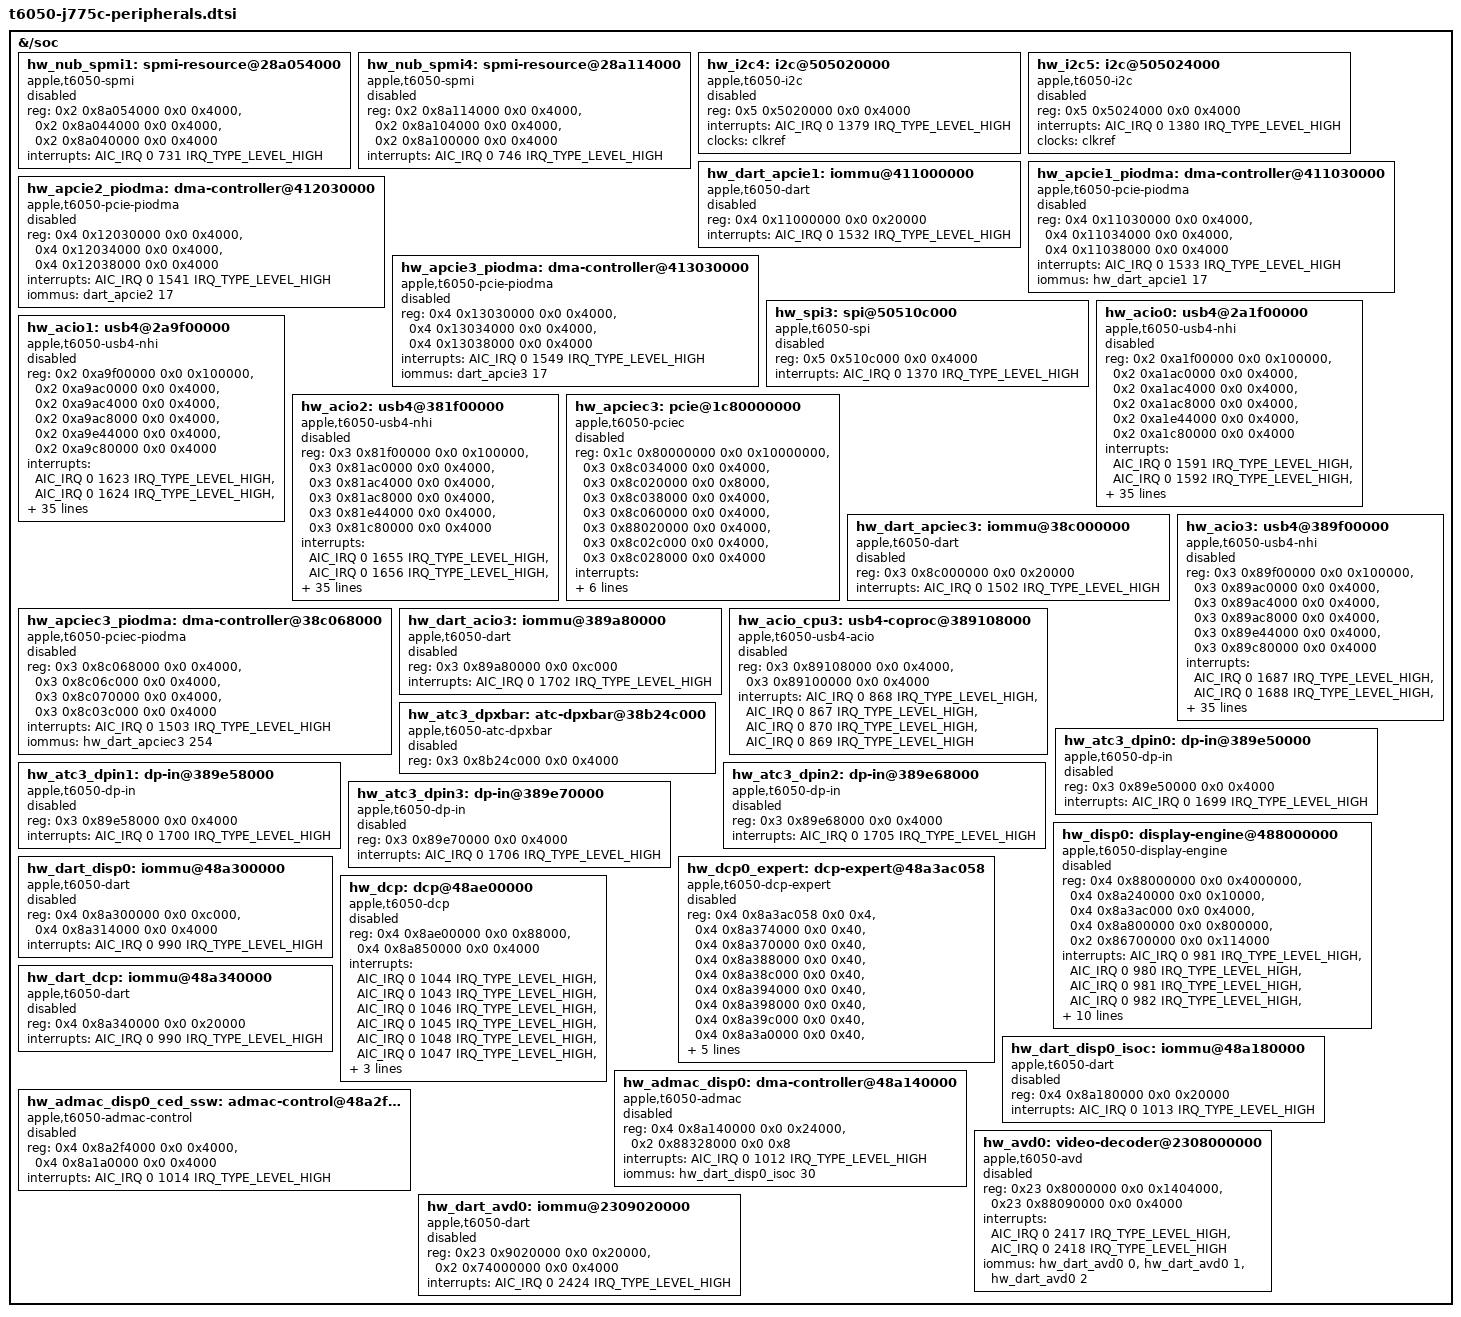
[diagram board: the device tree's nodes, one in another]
#include "t6050-peripherals.dtsi"

// SPDX-License-Identifier: GPL-2.0+ OR MIT
/* Register and interrupt resources; ownership-sensitive blocks stay disabled. */

&{/soc} {
	hw_nub_spmi1: spmi-resource@28a054000 {
		compatible = "apple,t6050-spmi", "apple,spmi";
		reg = <0x2 0x8a054000 0x0 0x4000>,
		      <0x2 0x8a044000 0x0 0x4000>,
		      <0x2 0x8a040000 0x0 0x4000>;
		status = "disabled";
		interrupts = <AIC_IRQ 0 731 IRQ_TYPE_LEVEL_HIGH>;
	};

	hw_nub_spmi4: spmi-resource@28a114000 {
		compatible = "apple,t6050-spmi", "apple,spmi";
		reg = <0x2 0x8a114000 0x0 0x4000>,
		      <0x2 0x8a104000 0x0 0x4000>,
		      <0x2 0x8a100000 0x0 0x4000>;
		status = "disabled";
		interrupts = <AIC_IRQ 0 746 IRQ_TYPE_LEVEL_HIGH>;
	};

	hw_i2c4: i2c@505020000 {
		compatible = "apple,t6050-i2c", "apple,t8103-i2c";
		reg = <0x5 0x5020000 0x0 0x4000>;
		interrupts = <AIC_IRQ 0 1379 IRQ_TYPE_LEVEL_HIGH>;
		status = "disabled";
		clocks = <&clkref>;
		#address-cells = <1>;
		#size-cells = <0>;
	};

	hw_i2c5: i2c@505024000 {
		compatible = "apple,t6050-i2c", "apple,t8103-i2c";
		reg = <0x5 0x5024000 0x0 0x4000>;
		interrupts = <AIC_IRQ 0 1380 IRQ_TYPE_LEVEL_HIGH>;
		status = "disabled";
		clocks = <&clkref>;
		#address-cells = <1>;
		#size-cells = <0>;
	};

	hw_dart_apcie1: iommu@411000000 {
		compatible = "apple,t6050-dart", "apple,dart";
		reg = <0x4 0x11000000 0x0 0x20000>;
		#iommu-cells = <1>;
		interrupts = <AIC_IRQ 0 1532 IRQ_TYPE_LEVEL_HIGH>;
		status = "disabled";
	};

	hw_apcie1_piodma: dma-controller@411030000 {
		compatible = "apple,t6050-pcie-piodma", "apple,pcie-piodma";
		reg = <0x4 0x11030000 0x0 0x4000>,
		      <0x4 0x11034000 0x0 0x4000>,
		      <0x4 0x11038000 0x0 0x4000>;
		interrupts = <AIC_IRQ 0 1533 IRQ_TYPE_LEVEL_HIGH>;
		iommus = <&hw_dart_apcie1 17>;
		status = "disabled";
	};

	hw_apcie2_piodma: dma-controller@412030000 {
		compatible = "apple,t6050-pcie-piodma", "apple,pcie-piodma";
		reg = <0x4 0x12030000 0x0 0x4000>,
		      <0x4 0x12034000 0x0 0x4000>,
		      <0x4 0x12038000 0x0 0x4000>;
		interrupts = <AIC_IRQ 0 1541 IRQ_TYPE_LEVEL_HIGH>;
		iommus = <&dart_apcie2 17>;
		status = "disabled";
	};

	hw_apcie3_piodma: dma-controller@413030000 {
		compatible = "apple,t6050-pcie-piodma", "apple,pcie-piodma";
		reg = <0x4 0x13030000 0x0 0x4000>,
		      <0x4 0x13034000 0x0 0x4000>,
		      <0x4 0x13038000 0x0 0x4000>;
		interrupts = <AIC_IRQ 0 1549 IRQ_TYPE_LEVEL_HIGH>;
		iommus = <&dart_apcie3 17>;
		status = "disabled";
	};

	hw_spi3: spi@50510c000 {
		compatible = "apple,t6050-spi", "apple,spi";
		reg = <0x5 0x510c000 0x0 0x4000>;
		interrupts = <AIC_IRQ 0 1370 IRQ_TYPE_LEVEL_HIGH>;
		status = "disabled";
	};

	hw_acio0: usb4@2a1f00000 {
		compatible = "apple,t6050-usb4-nhi", "apple,usb4-nhi";
		reg = <0x2 0xa1f00000 0x0 0x100000>,
		      <0x2 0xa1ac0000 0x0 0x4000>,
		      <0x2 0xa1ac4000 0x0 0x4000>,
		      <0x2 0xa1ac8000 0x0 0x4000>,
		      <0x2 0xa1e44000 0x0 0x4000>,
		      <0x2 0xa1c80000 0x0 0x4000>;
		interrupts = <AIC_IRQ 0 1591 IRQ_TYPE_LEVEL_HIGH>,
			     <AIC_IRQ 0 1592 IRQ_TYPE_LEVEL_HIGH>,
			     <AIC_IRQ 0 1593 IRQ_TYPE_LEVEL_HIGH>,
			     <AIC_IRQ 0 1594 IRQ_TYPE_LEVEL_HIGH>,
			     <AIC_IRQ 0 1595 IRQ_TYPE_LEVEL_HIGH>,
			     <AIC_IRQ 0 1596 IRQ_TYPE_LEVEL_HIGH>,
			     <AIC_IRQ 0 1597 IRQ_TYPE_LEVEL_HIGH>,
			     <AIC_IRQ 0 1598 IRQ_TYPE_LEVEL_HIGH>,
			     <AIC_IRQ 0 1599 IRQ_TYPE_LEVEL_HIGH>,
			     <AIC_IRQ 0 1600 IRQ_TYPE_LEVEL_HIGH>,
			     <AIC_IRQ 0 1601 IRQ_TYPE_LEVEL_HIGH>,
			     <AIC_IRQ 0 1602 IRQ_TYPE_LEVEL_HIGH>,
			     <AIC_IRQ 0 1579 IRQ_TYPE_LEVEL_HIGH>,
			     <AIC_IRQ 0 1580 IRQ_TYPE_LEVEL_HIGH>,
			     <AIC_IRQ 0 1581 IRQ_TYPE_LEVEL_HIGH>,
			     <AIC_IRQ 0 1582 IRQ_TYPE_LEVEL_HIGH>,
			     <AIC_IRQ 0 1583 IRQ_TYPE_LEVEL_HIGH>,
			     <AIC_IRQ 0 1584 IRQ_TYPE_LEVEL_HIGH>,
			     <AIC_IRQ 0 1585 IRQ_TYPE_LEVEL_HIGH>,
			     <AIC_IRQ 0 1586 IRQ_TYPE_LEVEL_HIGH>,
			     <AIC_IRQ 0 1587 IRQ_TYPE_LEVEL_HIGH>,
			     <AIC_IRQ 0 1588 IRQ_TYPE_LEVEL_HIGH>,
			     <AIC_IRQ 0 1589 IRQ_TYPE_LEVEL_HIGH>,
			     <AIC_IRQ 0 1590 IRQ_TYPE_LEVEL_HIGH>,
			     <AIC_IRQ 0 1608 IRQ_TYPE_LEVEL_HIGH>;
		iommus = <&hw_dart_acio0 0>, <&hw_dart_acio0 1>, <&hw_dart_acio0 2>, <&hw_dart_acio0 3>, <&hw_dart_acio0 4>, <&hw_dart_acio0 5>, <&hw_dart_acio0 6>, <&hw_dart_acio0 7>, <&hw_dart_acio0 8>, <&hw_dart_acio0 9>, <&hw_dart_acio0 10>, <&hw_dart_acio0 11>, <&hw_dart_acio0 16>, <&hw_dart_acio0 17>, <&hw_dart_acio0 18>, <&hw_dart_acio0 19>, <&hw_dart_acio0 20>, <&hw_dart_acio0 21>, <&hw_dart_acio0 22>, <&hw_dart_acio0 23>, <&hw_dart_acio0 24>, <&hw_dart_acio0 25>, <&hw_dart_acio0 26>, <&hw_dart_acio0 27>;
		status = "disabled";
	};

	hw_acio1: usb4@2a9f00000 {
		compatible = "apple,t6050-usb4-nhi", "apple,usb4-nhi";
		reg = <0x2 0xa9f00000 0x0 0x100000>,
		      <0x2 0xa9ac0000 0x0 0x4000>,
		      <0x2 0xa9ac4000 0x0 0x4000>,
		      <0x2 0xa9ac8000 0x0 0x4000>,
		      <0x2 0xa9e44000 0x0 0x4000>,
		      <0x2 0xa9c80000 0x0 0x4000>;
		interrupts = <AIC_IRQ 0 1623 IRQ_TYPE_LEVEL_HIGH>,
			     <AIC_IRQ 0 1624 IRQ_TYPE_LEVEL_HIGH>,
			     <AIC_IRQ 0 1625 IRQ_TYPE_LEVEL_HIGH>,
			     <AIC_IRQ 0 1626 IRQ_TYPE_LEVEL_HIGH>,
			     <AIC_IRQ 0 1627 IRQ_TYPE_LEVEL_HIGH>,
			     <AIC_IRQ 0 1628 IRQ_TYPE_LEVEL_HIGH>,
			     <AIC_IRQ 0 1629 IRQ_TYPE_LEVEL_HIGH>,
			     <AIC_IRQ 0 1630 IRQ_TYPE_LEVEL_HIGH>,
			     <AIC_IRQ 0 1631 IRQ_TYPE_LEVEL_HIGH>,
			     <AIC_IRQ 0 1632 IRQ_TYPE_LEVEL_HIGH>,
			     <AIC_IRQ 0 1633 IRQ_TYPE_LEVEL_HIGH>,
			     <AIC_IRQ 0 1634 IRQ_TYPE_LEVEL_HIGH>,
			     <AIC_IRQ 0 1611 IRQ_TYPE_LEVEL_HIGH>,
			     <AIC_IRQ 0 1612 IRQ_TYPE_LEVEL_HIGH>,
			     <AIC_IRQ 0 1613 IRQ_TYPE_LEVEL_HIGH>,
			     <AIC_IRQ 0 1614 IRQ_TYPE_LEVEL_HIGH>,
			     <AIC_IRQ 0 1615 IRQ_TYPE_LEVEL_HIGH>,
			     <AIC_IRQ 0 1616 IRQ_TYPE_LEVEL_HIGH>,
			     <AIC_IRQ 0 1617 IRQ_TYPE_LEVEL_HIGH>,
			     <AIC_IRQ 0 1618 IRQ_TYPE_LEVEL_HIGH>,
			     <AIC_IRQ 0 1619 IRQ_TYPE_LEVEL_HIGH>,
			     <AIC_IRQ 0 1620 IRQ_TYPE_LEVEL_HIGH>,
			     <AIC_IRQ 0 1621 IRQ_TYPE_LEVEL_HIGH>,
			     <AIC_IRQ 0 1622 IRQ_TYPE_LEVEL_HIGH>,
			     <AIC_IRQ 0 1640 IRQ_TYPE_LEVEL_HIGH>;
		iommus = <&hw_dart_acio1 0>, <&hw_dart_acio1 1>, <&hw_dart_acio1 2>, <&hw_dart_acio1 3>, <&hw_dart_acio1 4>, <&hw_dart_acio1 5>, <&hw_dart_acio1 6>, <&hw_dart_acio1 7>, <&hw_dart_acio1 8>, <&hw_dart_acio1 9>, <&hw_dart_acio1 10>, <&hw_dart_acio1 11>, <&hw_dart_acio1 16>, <&hw_dart_acio1 17>, <&hw_dart_acio1 18>, <&hw_dart_acio1 19>, <&hw_dart_acio1 20>, <&hw_dart_acio1 21>, <&hw_dart_acio1 22>, <&hw_dart_acio1 23>, <&hw_dart_acio1 24>, <&hw_dart_acio1 25>, <&hw_dart_acio1 26>, <&hw_dart_acio1 27>;
		status = "disabled";
	};

	hw_acio2: usb4@381f00000 {
		compatible = "apple,t6050-usb4-nhi", "apple,usb4-nhi";
		reg = <0x3 0x81f00000 0x0 0x100000>,
		      <0x3 0x81ac0000 0x0 0x4000>,
		      <0x3 0x81ac4000 0x0 0x4000>,
		      <0x3 0x81ac8000 0x0 0x4000>,
		      <0x3 0x81e44000 0x0 0x4000>,
		      <0x3 0x81c80000 0x0 0x4000>;
		interrupts = <AIC_IRQ 0 1655 IRQ_TYPE_LEVEL_HIGH>,
			     <AIC_IRQ 0 1656 IRQ_TYPE_LEVEL_HIGH>,
			     <AIC_IRQ 0 1657 IRQ_TYPE_LEVEL_HIGH>,
			     <AIC_IRQ 0 1658 IRQ_TYPE_LEVEL_HIGH>,
			     <AIC_IRQ 0 1659 IRQ_TYPE_LEVEL_HIGH>,
			     <AIC_IRQ 0 1660 IRQ_TYPE_LEVEL_HIGH>,
			     <AIC_IRQ 0 1661 IRQ_TYPE_LEVEL_HIGH>,
			     <AIC_IRQ 0 1662 IRQ_TYPE_LEVEL_HIGH>,
			     <AIC_IRQ 0 1663 IRQ_TYPE_LEVEL_HIGH>,
			     <AIC_IRQ 0 1664 IRQ_TYPE_LEVEL_HIGH>,
			     <AIC_IRQ 0 1665 IRQ_TYPE_LEVEL_HIGH>,
			     <AIC_IRQ 0 1666 IRQ_TYPE_LEVEL_HIGH>,
			     <AIC_IRQ 0 1643 IRQ_TYPE_LEVEL_HIGH>,
			     <AIC_IRQ 0 1644 IRQ_TYPE_LEVEL_HIGH>,
			     <AIC_IRQ 0 1645 IRQ_TYPE_LEVEL_HIGH>,
			     <AIC_IRQ 0 1646 IRQ_TYPE_LEVEL_HIGH>,
			     <AIC_IRQ 0 1647 IRQ_TYPE_LEVEL_HIGH>,
			     <AIC_IRQ 0 1648 IRQ_TYPE_LEVEL_HIGH>,
			     <AIC_IRQ 0 1649 IRQ_TYPE_LEVEL_HIGH>,
			     <AIC_IRQ 0 1650 IRQ_TYPE_LEVEL_HIGH>,
			     <AIC_IRQ 0 1651 IRQ_TYPE_LEVEL_HIGH>,
			     <AIC_IRQ 0 1652 IRQ_TYPE_LEVEL_HIGH>,
			     <AIC_IRQ 0 1653 IRQ_TYPE_LEVEL_HIGH>,
			     <AIC_IRQ 0 1654 IRQ_TYPE_LEVEL_HIGH>,
			     <AIC_IRQ 0 1672 IRQ_TYPE_LEVEL_HIGH>;
		iommus = <&hw_dart_acio2 0>, <&hw_dart_acio2 1>, <&hw_dart_acio2 2>, <&hw_dart_acio2 3>, <&hw_dart_acio2 4>, <&hw_dart_acio2 5>, <&hw_dart_acio2 6>, <&hw_dart_acio2 7>, <&hw_dart_acio2 8>, <&hw_dart_acio2 9>, <&hw_dart_acio2 10>, <&hw_dart_acio2 11>, <&hw_dart_acio2 16>, <&hw_dart_acio2 17>, <&hw_dart_acio2 18>, <&hw_dart_acio2 19>, <&hw_dart_acio2 20>, <&hw_dart_acio2 21>, <&hw_dart_acio2 22>, <&hw_dart_acio2 23>, <&hw_dart_acio2 24>, <&hw_dart_acio2 25>, <&hw_dart_acio2 26>, <&hw_dart_acio2 27>;
		status = "disabled";
	};

	hw_apciec3: pcie@1c80000000 {
		compatible = "apple,t6050-pciec", "apple,pciec";
		reg = <0x1c 0x80000000 0x0 0x10000000>,
		      <0x3 0x8c034000 0x0 0x4000>,
		      <0x3 0x8c020000 0x0 0x8000>,
		      <0x3 0x8c038000 0x0 0x4000>,
		      <0x3 0x8c060000 0x0 0x4000>,
		      <0x3 0x88020000 0x0 0x4000>,
		      <0x3 0x8c02c000 0x0 0x4000>,
		      <0x3 0x8c028000 0x0 0x4000>;
		interrupts = <AIC_IRQ 0 1501 IRQ_TYPE_LEVEL_HIGH>,
			     <AIC_IRQ 0 1504 IRQ_TYPE_LEVEL_HIGH>,
			     <AIC_IRQ 0 1505 IRQ_TYPE_LEVEL_HIGH>,
			     <AIC_IRQ 0 1506 IRQ_TYPE_LEVEL_HIGH>,
			     <AIC_IRQ 0 1507 IRQ_TYPE_LEVEL_HIGH>,
			     <AIC_IRQ 0 1508 IRQ_TYPE_LEVEL_HIGH>;
		status = "disabled";
	};

	hw_dart_apciec3: iommu@38c000000 {
		compatible = "apple,t6050-dart", "apple,dart";
		reg = <0x3 0x8c000000 0x0 0x20000>;
		#iommu-cells = <1>;
		interrupts = <AIC_IRQ 0 1502 IRQ_TYPE_LEVEL_HIGH>;
		status = "disabled";
	};

	hw_apciec3_piodma: dma-controller@38c068000 {
		compatible = "apple,t6050-pciec-piodma", "apple,pciec-piodma";
		reg = <0x3 0x8c068000 0x0 0x4000>,
		      <0x3 0x8c06c000 0x0 0x4000>,
		      <0x3 0x8c070000 0x0 0x4000>,
		      <0x3 0x8c03c000 0x0 0x4000>;
		interrupts = <AIC_IRQ 0 1503 IRQ_TYPE_LEVEL_HIGH>;
		iommus = <&hw_dart_apciec3 254>;
		status = "disabled";
	};

	hw_acio3: usb4@389f00000 {
		compatible = "apple,t6050-usb4-nhi", "apple,usb4-nhi";
		reg = <0x3 0x89f00000 0x0 0x100000>,
		      <0x3 0x89ac0000 0x0 0x4000>,
		      <0x3 0x89ac4000 0x0 0x4000>,
		      <0x3 0x89ac8000 0x0 0x4000>,
		      <0x3 0x89e44000 0x0 0x4000>,
		      <0x3 0x89c80000 0x0 0x4000>;
		interrupts = <AIC_IRQ 0 1687 IRQ_TYPE_LEVEL_HIGH>,
			     <AIC_IRQ 0 1688 IRQ_TYPE_LEVEL_HIGH>,
			     <AIC_IRQ 0 1689 IRQ_TYPE_LEVEL_HIGH>,
			     <AIC_IRQ 0 1690 IRQ_TYPE_LEVEL_HIGH>,
			     <AIC_IRQ 0 1691 IRQ_TYPE_LEVEL_HIGH>,
			     <AIC_IRQ 0 1692 IRQ_TYPE_LEVEL_HIGH>,
			     <AIC_IRQ 0 1693 IRQ_TYPE_LEVEL_HIGH>,
			     <AIC_IRQ 0 1694 IRQ_TYPE_LEVEL_HIGH>,
			     <AIC_IRQ 0 1695 IRQ_TYPE_LEVEL_HIGH>,
			     <AIC_IRQ 0 1696 IRQ_TYPE_LEVEL_HIGH>,
			     <AIC_IRQ 0 1697 IRQ_TYPE_LEVEL_HIGH>,
			     <AIC_IRQ 0 1698 IRQ_TYPE_LEVEL_HIGH>,
			     <AIC_IRQ 0 1675 IRQ_TYPE_LEVEL_HIGH>,
			     <AIC_IRQ 0 1676 IRQ_TYPE_LEVEL_HIGH>,
			     <AIC_IRQ 0 1677 IRQ_TYPE_LEVEL_HIGH>,
			     <AIC_IRQ 0 1678 IRQ_TYPE_LEVEL_HIGH>,
			     <AIC_IRQ 0 1679 IRQ_TYPE_LEVEL_HIGH>,
			     <AIC_IRQ 0 1680 IRQ_TYPE_LEVEL_HIGH>,
			     <AIC_IRQ 0 1681 IRQ_TYPE_LEVEL_HIGH>,
			     <AIC_IRQ 0 1682 IRQ_TYPE_LEVEL_HIGH>,
			     <AIC_IRQ 0 1683 IRQ_TYPE_LEVEL_HIGH>,
			     <AIC_IRQ 0 1684 IRQ_TYPE_LEVEL_HIGH>,
			     <AIC_IRQ 0 1685 IRQ_TYPE_LEVEL_HIGH>,
			     <AIC_IRQ 0 1686 IRQ_TYPE_LEVEL_HIGH>,
			     <AIC_IRQ 0 1704 IRQ_TYPE_LEVEL_HIGH>;
		iommus = <&hw_dart_acio3 0>, <&hw_dart_acio3 1>, <&hw_dart_acio3 2>, <&hw_dart_acio3 3>, <&hw_dart_acio3 4>, <&hw_dart_acio3 5>, <&hw_dart_acio3 6>, <&hw_dart_acio3 7>, <&hw_dart_acio3 8>, <&hw_dart_acio3 9>, <&hw_dart_acio3 10>, <&hw_dart_acio3 11>, <&hw_dart_acio3 16>, <&hw_dart_acio3 17>, <&hw_dart_acio3 18>, <&hw_dart_acio3 19>, <&hw_dart_acio3 20>, <&hw_dart_acio3 21>, <&hw_dart_acio3 22>, <&hw_dart_acio3 23>, <&hw_dart_acio3 24>, <&hw_dart_acio3 25>, <&hw_dart_acio3 26>, <&hw_dart_acio3 27>;
		status = "disabled";
	};

	hw_dart_acio3: iommu@389a80000 {
		compatible = "apple,t6050-dart", "apple,dart";
		reg = <0x3 0x89a80000 0x0 0xc000>;
		#iommu-cells = <1>;
		interrupts = <AIC_IRQ 0 1702 IRQ_TYPE_LEVEL_HIGH>;
		status = "disabled";
	};

	hw_acio_cpu3: usb4-coproc@389108000 {
		compatible = "apple,t6050-usb4-acio", "apple,usb4-acio";
		reg = <0x3 0x89108000 0x0 0x4000>,
		      <0x3 0x89100000 0x0 0x4000>;
		interrupts = <AIC_IRQ 0 868 IRQ_TYPE_LEVEL_HIGH>,
			     <AIC_IRQ 0 867 IRQ_TYPE_LEVEL_HIGH>,
			     <AIC_IRQ 0 870 IRQ_TYPE_LEVEL_HIGH>,
			     <AIC_IRQ 0 869 IRQ_TYPE_LEVEL_HIGH>;
		status = "disabled";
	};

	hw_atc3_dpxbar: atc-dpxbar@38b24c000 {
		compatible = "apple,t6050-atc-dpxbar", "apple,atc-dpxbar";
		reg = <0x3 0x8b24c000 0x0 0x4000>;
		status = "disabled";
	};

	hw_atc3_dpin0: dp-in@389e50000 {
		compatible = "apple,t6050-dp-in", "apple,dp-in";
		reg = <0x3 0x89e50000 0x0 0x4000>;
		interrupts = <AIC_IRQ 0 1699 IRQ_TYPE_LEVEL_HIGH>;
		status = "disabled";
	};

	hw_atc3_dpin1: dp-in@389e58000 {
		compatible = "apple,t6050-dp-in", "apple,dp-in";
		reg = <0x3 0x89e58000 0x0 0x4000>;
		interrupts = <AIC_IRQ 0 1700 IRQ_TYPE_LEVEL_HIGH>;
		status = "disabled";
	};

	hw_atc3_dpin2: dp-in@389e68000 {
		compatible = "apple,t6050-dp-in", "apple,dp-in";
		reg = <0x3 0x89e68000 0x0 0x4000>;
		interrupts = <AIC_IRQ 0 1705 IRQ_TYPE_LEVEL_HIGH>;
		status = "disabled";
	};

	hw_atc3_dpin3: dp-in@389e70000 {
		compatible = "apple,t6050-dp-in", "apple,dp-in";
		reg = <0x3 0x89e70000 0x0 0x4000>;
		interrupts = <AIC_IRQ 0 1706 IRQ_TYPE_LEVEL_HIGH>;
		status = "disabled";
	};

	hw_disp0: display-engine@488000000 {
		compatible = "apple,t6050-display-engine", "apple,display-engine";
		reg = <0x4 0x88000000 0x0 0x4000000>,
		      <0x4 0x8a240000 0x0 0x10000>,
		      <0x4 0x8a3ac000 0x0 0x4000>,
		      <0x4 0x8a800000 0x0 0x800000>,
		      <0x2 0x86700000 0x0 0x114000>;
		interrupts = <AIC_IRQ 0 981 IRQ_TYPE_LEVEL_HIGH>,
			     <AIC_IRQ 0 980 IRQ_TYPE_LEVEL_HIGH>,
			     <AIC_IRQ 0 981 IRQ_TYPE_LEVEL_HIGH>,
			     <AIC_IRQ 0 982 IRQ_TYPE_LEVEL_HIGH>,
			     <AIC_IRQ 0 983 IRQ_TYPE_LEVEL_HIGH>,
			     <AIC_IRQ 0 984 IRQ_TYPE_LEVEL_HIGH>,
			     <AIC_IRQ 0 985 IRQ_TYPE_LEVEL_HIGH>,
			     <AIC_IRQ 0 986 IRQ_TYPE_LEVEL_HIGH>,
			     <AIC_IRQ 0 987 IRQ_TYPE_LEVEL_HIGH>,
			     <AIC_IRQ 0 988 IRQ_TYPE_LEVEL_HIGH>,
			     <AIC_IRQ 0 989 IRQ_TYPE_LEVEL_HIGH>,
			     <AIC_IRQ 0 990 IRQ_TYPE_LEVEL_HIGH>,
			     <AIC_IRQ 0 1000 IRQ_TYPE_LEVEL_HIGH>;
		iommus = <&hw_dart_disp0 0>, <&hw_dart_disp0 16>;
		status = "disabled";
	};

	hw_dart_disp0: iommu@48a300000 {
		compatible = "apple,t6050-dart", "apple,dart";
		reg = <0x4 0x8a300000 0x0 0xc000>,
		      <0x4 0x8a314000 0x0 0x4000>;
		#iommu-cells = <1>;
		interrupts = <AIC_IRQ 0 990 IRQ_TYPE_LEVEL_HIGH>;
		status = "disabled";
	};

	hw_dcp0_expert: dcp-expert@48a3ac058 {
		compatible = "apple,t6050-dcp-expert", "apple,dcp-expert";
		reg = <0x4 0x8a3ac058 0x0 0x4>,
		      <0x4 0x8a374000 0x0 0x40>,
		      <0x4 0x8a370000 0x0 0x40>,
		      <0x4 0x8a388000 0x0 0x40>,
		      <0x4 0x8a38c000 0x0 0x40>,
		      <0x4 0x8a394000 0x0 0x40>,
		      <0x4 0x8a398000 0x0 0x40>,
		      <0x4 0x8a39c000 0x0 0x40>,
		      <0x4 0x8a3a0000 0x0 0x40>,
		      <0x4 0x88208000 0x0 0x40>,
		      <0x4 0x8820c000 0x0 0x40>,
		      <0x4 0x88210000 0x0 0x40>,
		      <0x4 0x88214000 0x0 0x40>;
		interrupts = <AIC_IRQ 0 985 IRQ_TYPE_LEVEL_HIGH>;
		status = "disabled";
	};

	hw_dcp: dcp@48ae00000 {
		compatible = "apple,t6050-dcp", "apple,dcp";
		reg = <0x4 0x8ae00000 0x0 0x88000>,
		      <0x4 0x8a850000 0x0 0x4000>;
		interrupts = <AIC_IRQ 0 1044 IRQ_TYPE_LEVEL_HIGH>,
			     <AIC_IRQ 0 1043 IRQ_TYPE_LEVEL_HIGH>,
			     <AIC_IRQ 0 1046 IRQ_TYPE_LEVEL_HIGH>,
			     <AIC_IRQ 0 1045 IRQ_TYPE_LEVEL_HIGH>,
			     <AIC_IRQ 0 1048 IRQ_TYPE_LEVEL_HIGH>,
			     <AIC_IRQ 0 1047 IRQ_TYPE_LEVEL_HIGH>,
			     <AIC_IRQ 0 1050 IRQ_TYPE_LEVEL_HIGH>,
			     <AIC_IRQ 0 1049 IRQ_TYPE_LEVEL_HIGH>;
		iommus = <&hw_dart_dcp 23>, <&hw_dart_dcp 24>;
		status = "disabled";
	};

	hw_dart_dcp: iommu@48a340000 {
		compatible = "apple,t6050-dart", "apple,dart";
		reg = <0x4 0x8a340000 0x0 0x20000>;
		#iommu-cells = <1>;
		interrupts = <AIC_IRQ 0 990 IRQ_TYPE_LEVEL_HIGH>;
		status = "disabled";
	};

	hw_dart_disp0_isoc: iommu@48a180000 {
		compatible = "apple,t6050-dart", "apple,dart";
		reg = <0x4 0x8a180000 0x0 0x20000>;
		#iommu-cells = <1>;
		interrupts = <AIC_IRQ 0 1013 IRQ_TYPE_LEVEL_HIGH>;
		status = "disabled";
	};

	hw_admac_disp0: dma-controller@48a140000 {
		compatible = "apple,t6050-admac", "apple,admac";
		reg = <0x4 0x8a140000 0x0 0x24000>,
		      <0x2 0x88328000 0x0 0x8>;
		interrupts = <AIC_IRQ 0 1012 IRQ_TYPE_LEVEL_HIGH>;
		iommus = <&hw_dart_disp0_isoc 30>;
		status = "disabled";
		#dma-cells = <1>;
	};

	hw_admac_disp0_ced_ssw: admac-control@48a2f4000 {
		compatible = "apple,t6050-admac-control", "apple,admac-control";
		reg = <0x4 0x8a2f4000 0x0 0x4000>,
		      <0x4 0x8a1a0000 0x0 0x4000>;
		interrupts = <AIC_IRQ 0 1014 IRQ_TYPE_LEVEL_HIGH>;
		status = "disabled";
	};

	hw_avd0: video-decoder@2308000000 {
		compatible = "apple,t6050-avd", "apple,avd";
		reg = <0x23 0x8000000 0x0 0x1404000>,
		      <0x23 0x88090000 0x0 0x4000>;
		interrupts = <AIC_IRQ 0 2417 IRQ_TYPE_LEVEL_HIGH>,
			     <AIC_IRQ 0 2418 IRQ_TYPE_LEVEL_HIGH>;
		iommus = <&hw_dart_avd0 0>, <&hw_dart_avd0 1>, <&hw_dart_avd0 2>;
		status = "disabled";
	};

	hw_dart_avd0: iommu@2309020000 {
		compatible = "apple,t6050-dart", "apple,dart";
		reg = <0x23 0x9020000 0x0 0x20000>,
		      <0x2 0x74000000 0x0 0x4000>;
		#iommu-cells = <1>;
		interrupts = <AIC_IRQ 0 2424 IRQ_TYPE_LEVEL_HIGH>;
		status = "disabled";
	};


};
